# STM32U5G9xx register map
File version: 1.0
Registers are 32-bit, read-write, reset 0x0 unless marked. A register's access mark holds for its fields unless they carry their own. Offsets are from the block's base; [hi:lo] are bit positions; {n}, {i} and the like mark numbered series; 'fields as' and 'values as' point back to an identical list.

## RAMCFG
Base 0x40026000
Same registers: RAMCFG_S 0x50026000
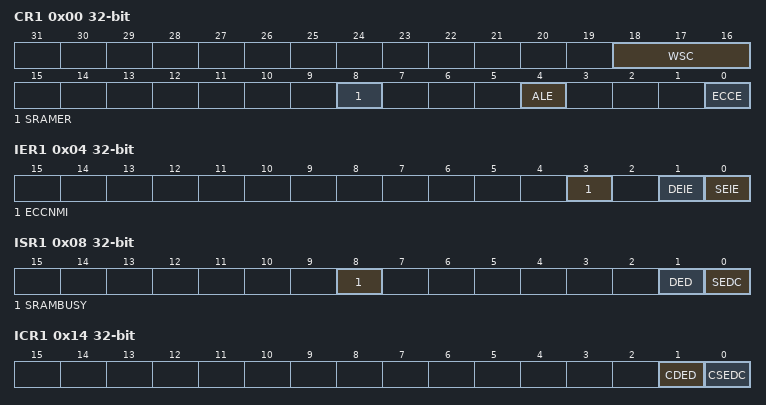
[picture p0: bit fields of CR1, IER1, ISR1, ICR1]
0x00 CR1 — Control Register
  [18:16] WSC — WSC[18:16] Wait State Configuration field
  [8] SRAMER — Start Erase
  [4] ALE — Address Latching Enable
  [0] ECCE — ECC Enable
0x04 IER1 — Interrupt Enable Register
  [3] ECCNMI — NMI redirection interrupt
  [1] DEIE — Double Error Interrupt Enable
  [0] SEIE — Single Error Interrupt Enable
0x08 ISR1 — Interrupt Status Register
  [8] SRAMBUSY — SRAM busy flag
  [1] DED — Double Error Detected flag
  [0] SEDC — Single Error Detected and Corrected flag
0x0C SEAR1 — ECC Single Error Address Register
  [31:0] ESEA — ECC Single Error Address
0x10 DEAR1 — ECC Double Error Address Register
  [31:0] EDEA — ECC Double Error Address
0x14 ICR1 — Interrupt Clear Register
  [1] CDED — Clear ECC Double Error Detected Flag
  [0] CSEDC — Clear ECC Single Error Detected and Corrected Flag
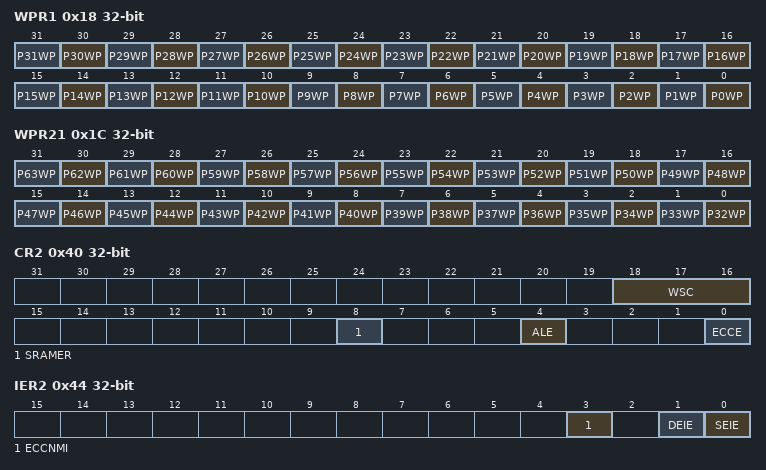
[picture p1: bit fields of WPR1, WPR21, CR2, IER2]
0x18 WPR1 — SRAM Write Protection Register 1
  [n] P{n}WP (n=0..31) — Write Protection Page {n:02}
0x1C WPR21 — SRAM Write Protection Register 2
  [n-32] P{n}WP (n=32..63) — Write Protection Page {n}
0x24 ECCKEY1 — SRAM ECC Key Register
0x28 ERKEYR1 — SRAM Erase Key Register
  [7:0] ERASEKEY — Erase Write Protection Key
0x40 CR2 — Control Register
  fields as CR1
0x44 IER2 — Interrupt Enable Register
  fields as IER1
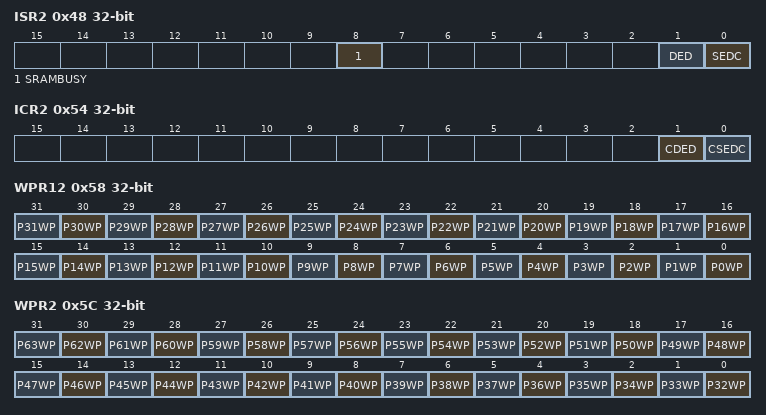
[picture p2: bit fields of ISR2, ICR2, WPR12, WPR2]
0x48 ISR2 — Interrupt Status Register
  fields as ISR1
0x4C SEAR2 — ECC Single Error Address Register
  [31:0] ESEA — ECC Single Error Address
0x50 DEAR2 — ECC Double Error Address Register
  [31:0] EDEA — ECC Double Error Address
0x54 ICR2 — Interrupt Clear Register
  fields as ICR1
0x58 WPR12 — SRAM Write Protection Register 1
  [n] P{n}WP (n=0..31) — Write Protection Page {n:02}
0x5C WPR2 — SRAM Write Protection Register 2
  [n-32] P{n}WP (n=32..63) — Write Protection Page {n}
0x64 ECCKEY2 — SRAM ECC Key Register
0x68 ERKEYR2 — SRAM Erase Key Register
  [7:0] ERASEKEY — Erase Write Protection Key
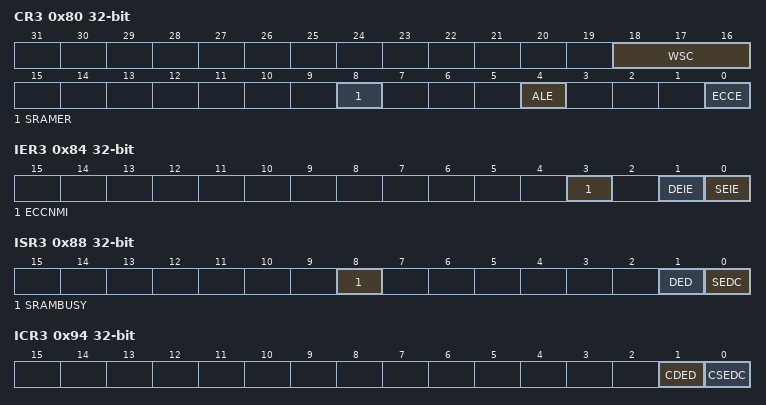
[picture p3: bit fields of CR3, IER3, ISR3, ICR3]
0x80 CR3 — Control Register
  fields as CR1
0x84 IER3 — Interrupt Enable Register
  fields as IER1
0x88 ISR3 — Interrupt Status Register
  fields as ISR1
0x8C SEAR3 — ECC Single Error Address Register
  [31:0] ESEA — ECC Single Error Address
0x90 DEAR3 — ECC Double Error Address Register
  [31:0] EDEA — ECC Double Error Address
0x94 ICR3 — Interrupt Clear Register
  fields as ICR1
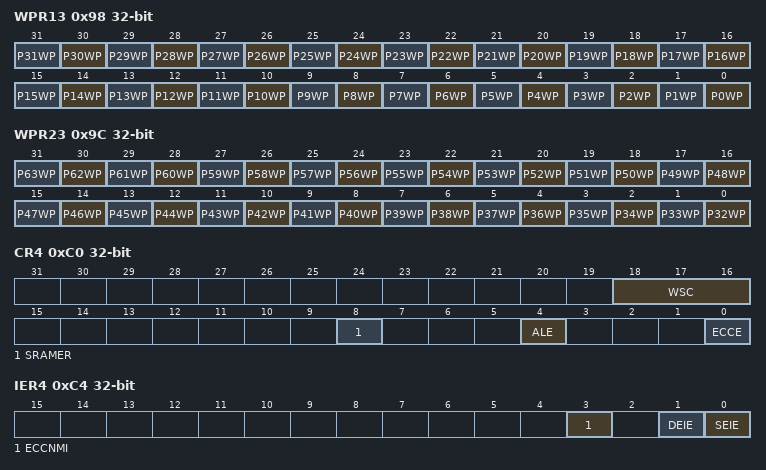
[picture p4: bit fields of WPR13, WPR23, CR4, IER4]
0x98 WPR13 — SRAM Write Protection Register 1
  [n] P{n}WP (n=0..31) — Write Protection Page {n:02}
0x9C WPR23 — SRAM Write Protection Register 2
  [n-32] P{n}WP (n=32..63) — Write Protection Page {n}
0xA4 ECCKEY3 — SRAM ECC Key Register
0xA8 ERKEYR3 — SRAM Erase Key Register
  [7:0] ERASEKEY — Erase Write Protection Key
0xC0 CR4 — Control Register
  fields as CR1
0xC4 IER4 — Interrupt Enable Register
  fields as IER1
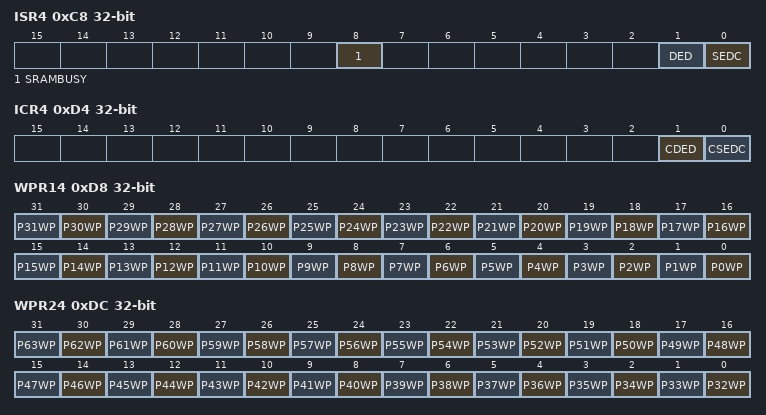
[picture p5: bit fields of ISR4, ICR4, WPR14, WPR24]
0xC8 ISR4 — Interrupt Status Register
  fields as ISR1
0xCC SEAR4 — ECC Single Error Address Register
  [31:0] ESEA — ECC Single Error Address
0xD0 DEAR4 — ECC Double Error Address Register
  [31:0] EDEA — ECC Double Error Address
0xD4 ICR4 — Interrupt Clear Register
  fields as ICR1
0xD8 WPR14 — SRAM Write Protection Register 1
  [n] P{n}WP (n=0..31) — Write Protection Page {n:02}
0xDC WPR24 — SRAM Write Protection Register 2
  [n-32] P{n}WP (n=32..63) — Write Protection Page {n}
0xE4 ECCKEY4 — SRAM ECC Key Register
0xE8 ERKEYR4 — SRAM Erase Key Register
  [7:0] ERASEKEY — Erase Write Protection Key
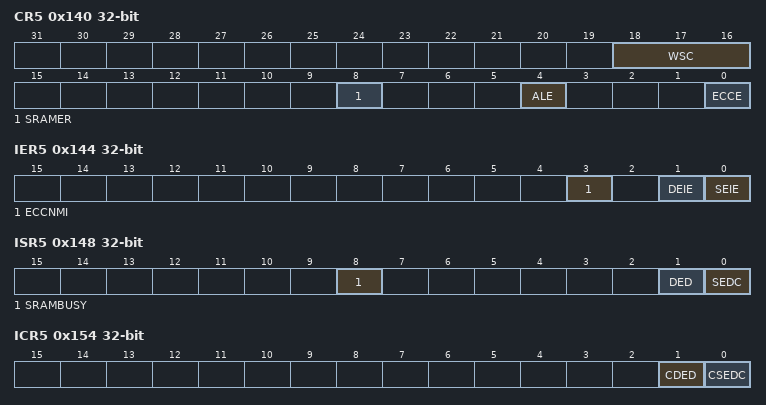
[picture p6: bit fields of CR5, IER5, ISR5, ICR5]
0x140 CR5 — Control Register
  fields as CR1
0x144 IER5 — Interrupt Enable Register
  fields as IER1
0x148 ISR5 — Interrupt Status Register
  fields as ISR1
0x14C SEAR5 — ECC Single Error Address Register
  [31:0] ESEA — ECC Single Error Address
0x150 DEAR5 — ECC Double Error Address Register
  [31:0] EDEA — ECC Double Error Address
0x154 ICR5 — Interrupt Clear Register
  fields as ICR1
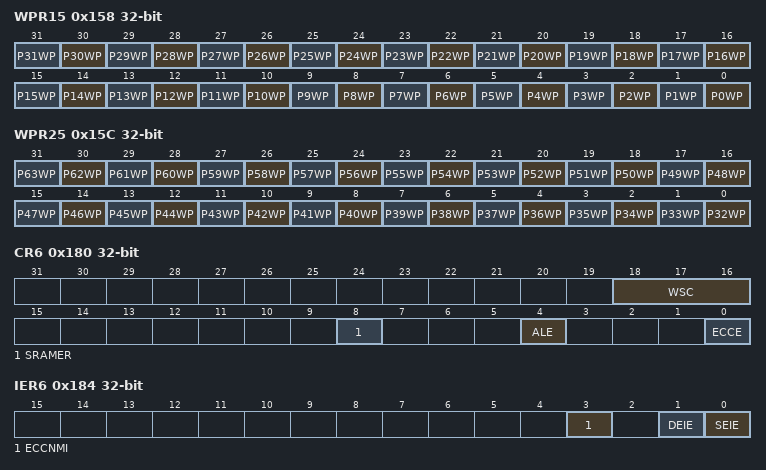
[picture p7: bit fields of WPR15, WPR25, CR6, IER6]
0x158 WPR15 — SRAM Write Protection Register 1
  [n] P{n}WP (n=0..31) — Write Protection Page {n:02}
0x15C WPR25 — SRAM Write Protection Register 2
  [n-32] P{n}WP (n=32..63) — Write Protection Page {n}
0x164 ECCKEY5 — SRAM ECC Key Register
0x168 ERKEYR5 — SRAM Erase Key Register
  [7:0] ERASEKEY — Erase Write Protection Key
0x180 CR6 — Control Register
  fields as CR1
0x184 IER6 — Interrupt Enable Register
  fields as IER1
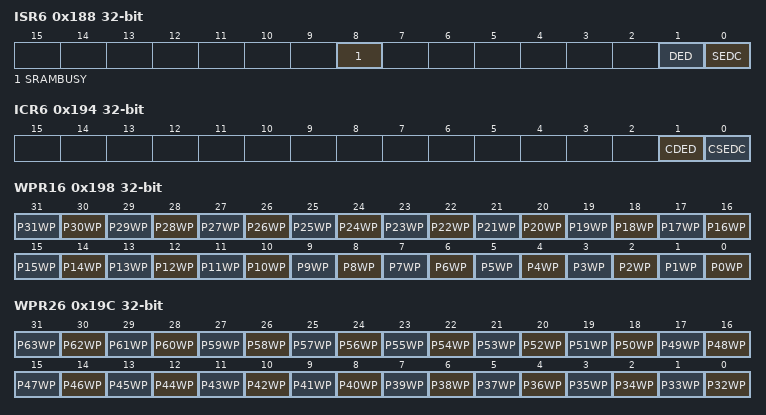
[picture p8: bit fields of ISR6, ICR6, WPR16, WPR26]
0x188 ISR6 — Interrupt Status Register
  fields as ISR1
0x18C SEAR6 — ECC Single Error Address Register
  [31:0] ESEA — ECC Single Error Address
0x190 DEAR6 — ECC Double Error Address Register
  [31:0] EDEA — ECC Double Error Address
0x194 ICR6 — Interrupt Clear Register
  fields as ICR1
0x198 WPR16 — SRAM Write Protection Register 1
  [n] P{n}WP (n=0..31) — Write Protection Page {n:02}
0x19C WPR26 — SRAM Write Protection Register 2
  [n-32] P{n}WP (n=32..63) — Write Protection Page {n}
0x1A4 ECCKEY6 — SRAM ECC Key Register
0x1A8 ERKEYR6 — SRAM Erase Key Register
  [7:0] ERASEKEY — Erase Write Protection Key
